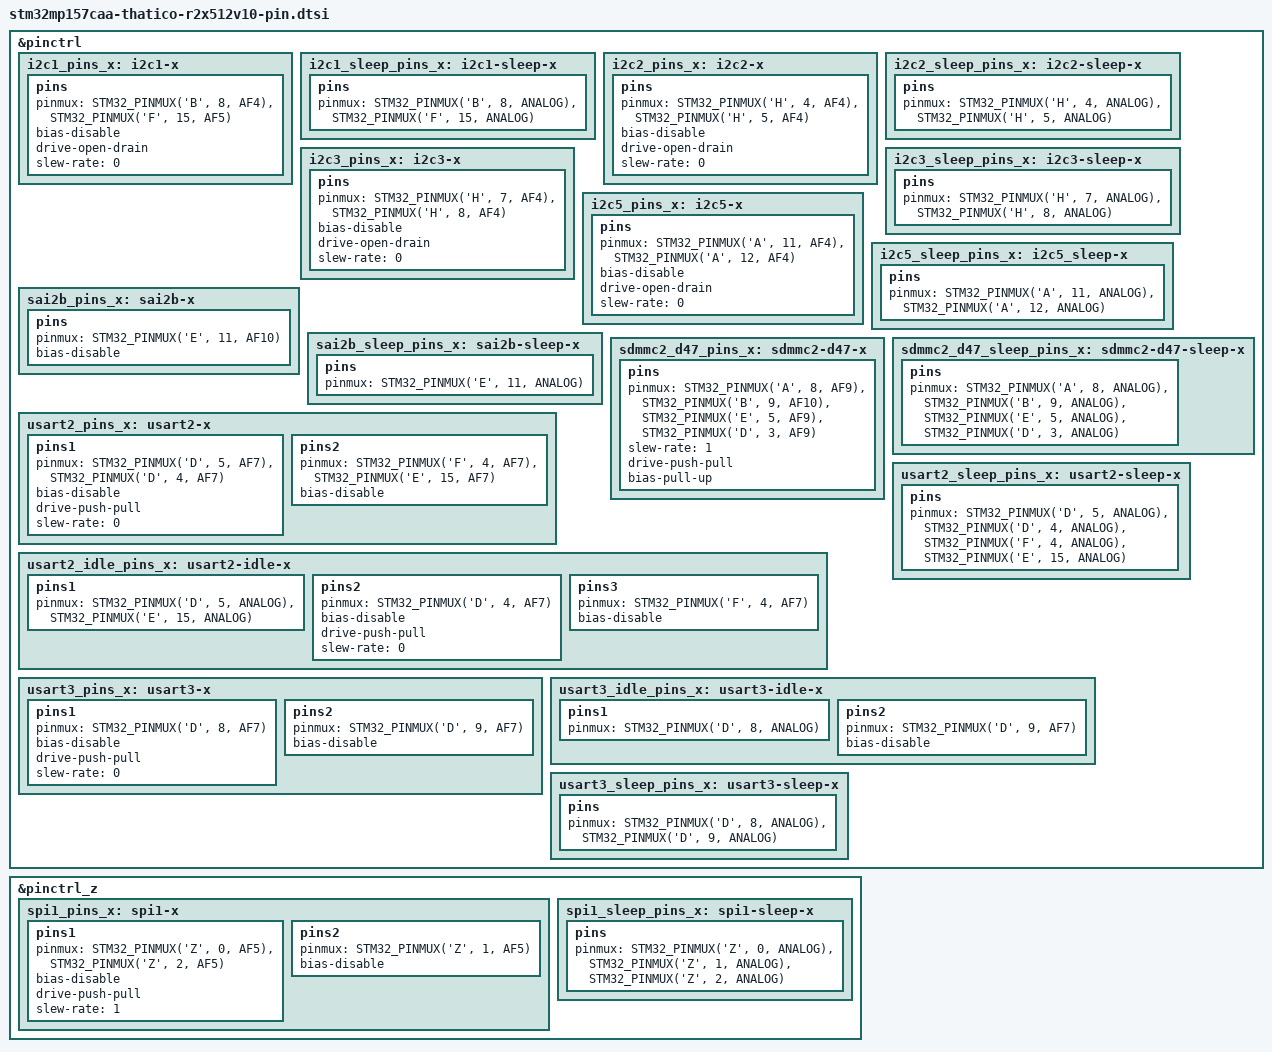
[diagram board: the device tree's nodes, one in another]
// SPDX-License-Identifier: (GPL-2.0+ OR BSD-3-Clause)
/*
 * Copyright (C) OneKiwi 2022 - All Rights Reserved
 * Author: Thanh Duong <thanh.duong.vs@gmail.com> for OneKiwi.
 */
#include <dt-bindings/pinctrl/stm32-pinfunc.h>

&pinctrl {

	i2c1_pins_x: i2c1-x {
		pins {
			pinmux = <STM32_PINMUX('B', 8, AF4)>, /* I2C1_SCL */
				 <STM32_PINMUX('F', 15, AF5)>; /* I2C1_SDA */
			bias-disable;
			drive-open-drain;
			slew-rate = <0>;
		};
	};

	i2c1_sleep_pins_x: i2c1-sleep-x {
		pins {
			pinmux = <STM32_PINMUX('B', 8, ANALOG)>, /* I2C1_SCL */
				 <STM32_PINMUX('F', 15, ANALOG)>; /* I2C1_SDA */
		};
	};

	i2c2_pins_x: i2c2-x {
		pins {
			pinmux = <STM32_PINMUX('H', 4, AF4)>, /* I2C2_SCL */
				 <STM32_PINMUX('H', 5, AF4)>; /* I2C2_SDA */
			bias-disable;
			drive-open-drain;
			slew-rate = <0>;
		};
	};

	i2c2_sleep_pins_x: i2c2-sleep-x {
		pins {
			pinmux = <STM32_PINMUX('H', 4, ANALOG)>, /* I2C2_SCL */
				 <STM32_PINMUX('H', 5, ANALOG)>; /* I2C2_SDA */
		};
	};

	i2c3_pins_x: i2c3-x {
		pins {
			pinmux = <STM32_PINMUX('H', 7, AF4)>, /* I2C3_SCL */
				 <STM32_PINMUX('H', 8, AF4)>; /* I2C3_SDA */
			bias-disable;
			drive-open-drain;
			slew-rate = <0>;
		};
	};

	i2c3_sleep_pins_x: i2c3-sleep-x {
		pins {
			pinmux = <STM32_PINMUX('H', 7, ANALOG)>, /* I2C3_SCL */
				 <STM32_PINMUX('H', 8, ANALOG)>; /* I2C3_SDA */
		};
	};

	i2c5_pins_x: i2c5-x {
		pins {
			pinmux = <STM32_PINMUX('A', 11, AF4)>, /* I2C5_SCL */
					 <STM32_PINMUX('A', 12, AF4)>; /* I2C5_SDA */
			bias-disable;
			drive-open-drain;
			slew-rate = <0>;
		};
	};

	i2c5_sleep_pins_x: i2c5_sleep-x {
		pins {
			pinmux = <STM32_PINMUX('A', 11, ANALOG)>, /* I2C5_SCL */
					 <STM32_PINMUX('A', 12, ANALOG)>; /* I2C5_SDA */
		};
	};

	sai2b_pins_x: sai2b-x {
		pins {
			pinmux = <STM32_PINMUX('E', 11, AF10)>; /* SAI2_SD_B */
			bias-disable;
		};
	};

	sai2b_sleep_pins_x: sai2b-sleep-x {
		pins {
			pinmux = <STM32_PINMUX('E', 11, ANALOG)>; /* SAI2_SD_B */
		};
	};

	sdmmc2_d47_pins_x: sdmmc2-d47-x {
		pins {
			pinmux = <STM32_PINMUX('A', 8, AF9)>, /* SDMMC2_D4 */
				 <STM32_PINMUX('B', 9, AF10)>, /* SDMMC2_D5 */
				 <STM32_PINMUX('E', 5, AF9)>, /* SDMMC2_D6 */
				 <STM32_PINMUX('D', 3, AF9)>; /* SDMMC2_D7 */
			slew-rate = <1>;
			drive-push-pull;
			bias-pull-up;
		};
	};

	sdmmc2_d47_sleep_pins_x: sdmmc2-d47-sleep-x {
		pins {
			pinmux = <STM32_PINMUX('A', 8, ANALOG)>, /* SDMMC2_D4 */
				 <STM32_PINMUX('B', 9, ANALOG)>, /* SDMMC2_D5 */
				 <STM32_PINMUX('E', 5, ANALOG)>, /* SDMMC2_D6 */
				 <STM32_PINMUX('D', 3, ANALOG)>; /* SDMMC2_D7 */
		};
	};

	usart2_pins_x: usart2-x {
		pins1 {
			pinmux = <STM32_PINMUX('D', 5, AF7)>, /* USART2_TX */
				 <STM32_PINMUX('D', 4, AF7)>; /* USART2_RTS */
			bias-disable;
			drive-push-pull;
			slew-rate = <0>;
		};
		pins2 {
			pinmux = <STM32_PINMUX('F', 4, AF7)>, /* USART2_RX */
				 <STM32_PINMUX('E', 15, AF7)>; /* USART2_CTS */
			bias-disable;
		};
	};

	usart2_idle_pins_x: usart2-idle-x {
		pins1 {
			pinmux = <STM32_PINMUX('D', 5, ANALOG)>, /* USART2_TX */
				 <STM32_PINMUX('E', 15, ANALOG)>; /* USART2_CTS */
		};
		pins2 {
			pinmux = <STM32_PINMUX('D', 4, AF7)>; /* USART2_RTS */
			bias-disable;
			drive-push-pull;
			slew-rate = <0>;
		};
		pins3 {
			pinmux = <STM32_PINMUX('F', 4, AF7)>; /* USART2_RX */
			bias-disable;
		};
	};

	usart2_sleep_pins_x: usart2-sleep-x {
		pins {
			pinmux = <STM32_PINMUX('D', 5, ANALOG)>, /* USART2_TX */
				 <STM32_PINMUX('D', 4, ANALOG)>, /* USART2_RTS */
				 <STM32_PINMUX('F', 4, ANALOG)>, /* USART2_RX */
				 <STM32_PINMUX('E', 15, ANALOG)>; /* USART2_CTS */
		};
	};

	usart3_pins_x: usart3-x {
		pins1 {
			pinmux = <STM32_PINMUX('D', 8, AF7)>; /* USART3_TX */
			bias-disable;
			drive-push-pull;
			slew-rate = <0>;
		};
		pins2 {
			pinmux = <STM32_PINMUX('D', 9, AF7)>; /* USART3_RX */
			bias-disable;
		};
	};

	usart3_idle_pins_x: usart3-idle-x {
		pins1 {
			pinmux = <STM32_PINMUX('D', 8, ANALOG)>; /* USART3_TX */
		};
		pins2 {
			pinmux = <STM32_PINMUX('D', 9, AF7)>; /* USART3_RX */
			bias-disable;
		};
	};

	usart3_sleep_pins_x: usart3-sleep-x {
		pins {
			pinmux = <STM32_PINMUX('D', 8, ANALOG)>, /* USART3_TX */
				 <STM32_PINMUX('D', 9, ANALOG)>; /* USART3_RX */
		};
	};
};

&pinctrl_z {
	spi1_pins_x: spi1-x {
		pins1 {
			pinmux = <STM32_PINMUX('Z', 0, AF5)>, /* SPI1_SCK */
				 <STM32_PINMUX('Z', 2, AF5)>; /* SPI1_MOSI */
			bias-disable;
			drive-push-pull;
			slew-rate = <1>;
		};

		pins2 {
			pinmux = <STM32_PINMUX('Z', 1, AF5)>; /* SPI1_MISO */
			bias-disable;
		};
	};

	spi1_sleep_pins_x: spi1-sleep-x {
		pins {
			pinmux = <STM32_PINMUX('Z', 0, ANALOG)>, /* SPI1_SCK */
				 <STM32_PINMUX('Z', 1, ANALOG)>, /* SPI1_MISO */
				 <STM32_PINMUX('Z', 2, ANALOG)>; /* SPI1_MOSI */
		};
	};
};
